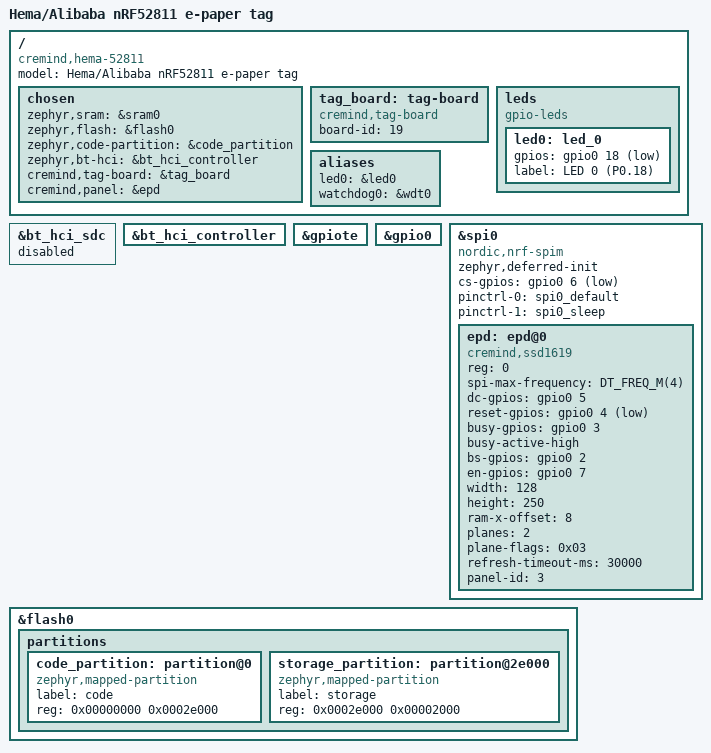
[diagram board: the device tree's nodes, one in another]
/*
 * Copyright (c) 2026 Cremind
 * SPDX-License-Identifier: MIT
 *
 * Hema/Alibaba nRF52811 e-paper tag, 2.13-inch (aesl0213c): nRF52811 QFAA
 * (192 KiB flash, 24 KiB SRAM). Pins and panel as documented by EPD-nRF5
 * (EPD_CFG_52811 and its "Hema213" panel: SSD1619, 128 x 250, RAM from column
 * 8). Bench-checked on one sample (docs/qualification/hema_52811.md); not
 * qualified yet (no panel-verified); wake sources unverified.
 */

/dts-v1/;
#include <nordic/nrf52811_qfaa.dtsi>
#include "hema_52811-pinctrl.dtsi"

/ {
	model = "Hema/Alibaba nRF52811 e-paper tag";
	compatible = "cremind,hema-52811";

	chosen {
		zephyr,sram = &sram0;
		zephyr,flash = &flash0;
		zephyr,code-partition = &code_partition;
		/* Zephyr controller on every target (docs/architecture.md). */
		zephyr,bt-hci = &bt_hci_controller;
		cremind,tag-board = &tag_board;
		cremind,panel = &epd;
	};

	tag_board: tag-board {
		compatible = "cremind,tag-board";
		board-id = <19>;
		/* Wake sources unverified: none described. */
	};

	leds {
		compatible = "gpio-leds";

		led0: led_0 {
			gpios = <&gpio0 18 GPIO_ACTIVE_LOW>;
			label = "LED 0 (P0.18)";
		};
	};

	aliases {
		led0 = &led0;
		watchdog0 = &wdt0;
	};
};

&bt_hci_sdc {
	status = "disabled";
};

&bt_hci_controller {
	status = "okay";
};

&gpiote {
	status = "okay";
};

&gpio0 {
	status = "okay";
};

/*
 * Deferred init: the bus starts in panel_init(), after the panel supply
 * (en-gpios) is on, so CS is never driven high into an unpowered panel.
 */
&spi0 {
	compatible = "nordic,nrf-spim";
	status = "okay";
	zephyr,deferred-init;
	cs-gpios = <&gpio0 6 GPIO_ACTIVE_LOW>;
	pinctrl-0 = <&spi0_default>;
	pinctrl-1 = <&spi0_sleep>;
	pinctrl-names = "default", "sleep";

	epd: epd@0 {
		compatible = "cremind,ssd1619";
		reg = <0>;
		spi-max-frequency = <DT_FREQ_M(4)>;
		dc-gpios = <&gpio0 5 GPIO_ACTIVE_HIGH>;
		reset-gpios = <&gpio0 4 GPIO_ACTIVE_LOW>;
		busy-gpios = <&gpio0 3 GPIO_ACTIVE_HIGH>;
		busy-active-high;
		bs-gpios = <&gpio0 2 GPIO_ACTIVE_HIGH>;
		en-gpios = <&gpio0 7 GPIO_ACTIVE_HIGH>;
		width = <128>;
		height = <250>;
		ram-x-offset = <8>;
		planes = <2>;
		plane-flags = <0x03>;
		refresh-timeout-ms = <30000>;
		panel-id = <3>;
	};
};

&flash0 {
	partitions {
		ranges;
		#address-cells = <1>;
		#size-cells = <1>;

		code_partition: partition@0 {
			compatible = "zephyr,mapped-partition";
			label = "code";
			reg = <0x00000000 0x0002e000>;
		};

		/* NVS: 2 x 4 KiB pages at the end of flash (docs/firmware-notes.md section 9). */
		storage_partition: partition@2e000 {
			compatible = "zephyr,mapped-partition";
			label = "storage";
			reg = <0x0002e000 0x00002000>;
		};
	};
};
